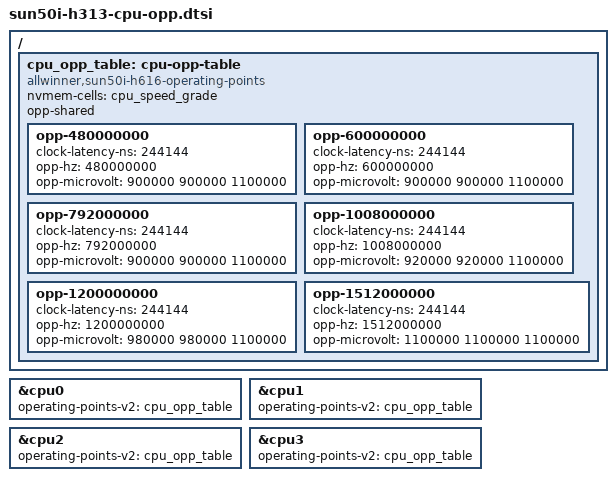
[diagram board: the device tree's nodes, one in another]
// SPDX-License-Identifier: (GPL-2.0+ OR MIT)
// Copyright (C) 2021 Piotr Oniszczuk <piotr.oniszczuk@gmail.com>

/*
	X96-q DDR3 vendor Android DT:
	480000000	900mV
	600000000	900mV
	792000000	900mV
	1008000000	920mV
	1200000000	980mV
	1344000000	1120mV
	1416000000	1140mV
	1512000000	1160mV
*/

/ {
	cpu_opp_table: cpu-opp-table {
		compatible = "allwinner,sun50i-h616-operating-points";
		nvmem-cells = <&cpu_speed_grade>;
		opp-shared;

		opp-480000000 {
			clock-latency-ns = <244144>; /* 8 32k periods */
			opp-hz = /bits/ 64 <480000000>;
			opp-microvolt = <900000 900000 1100000>;
		};

		opp-600000000 {
			clock-latency-ns = <244144>; /* 8 32k periods */
			opp-hz = /bits/ 64 <600000000>;
			opp-microvolt = <900000 900000 1100000>;
		};

		opp-792000000 {
			clock-latency-ns = <244144>; /* 8 32k periods */
			opp-hz = /bits/ 64 <792000000>;
		        opp-microvolt = <900000 900000 1100000>;
		};

		opp-1008000000 {
			clock-latency-ns = <244144>; /* 8 32k periods */
			opp-hz = /bits/ 64 <1008000000>;
			opp-microvolt = <920000 920000 1100000>;
		};

		opp-1200000000 {
			clock-latency-ns = <244144>; /* 8 32k periods */
			opp-hz = /bits/ 64 <1200000000>;
			opp-microvolt = <980000 980000 1100000>;
		};

		opp-1512000000 {
			clock-latency-ns = <244144>; /* 8 32k periods */
			opp-hz = /bits/ 64 <1512000000>;
			opp-microvolt = <1100000 1100000 1100000>;
		};
	};
};

&cpu0 {
	operating-points-v2 = <&cpu_opp_table>;
};

&cpu1 {
	operating-points-v2 = <&cpu_opp_table>;
};

&cpu2 {
	operating-points-v2 = <&cpu_opp_table>;
};

&cpu3 {
	operating-points-v2 = <&cpu_opp_table>;
};
